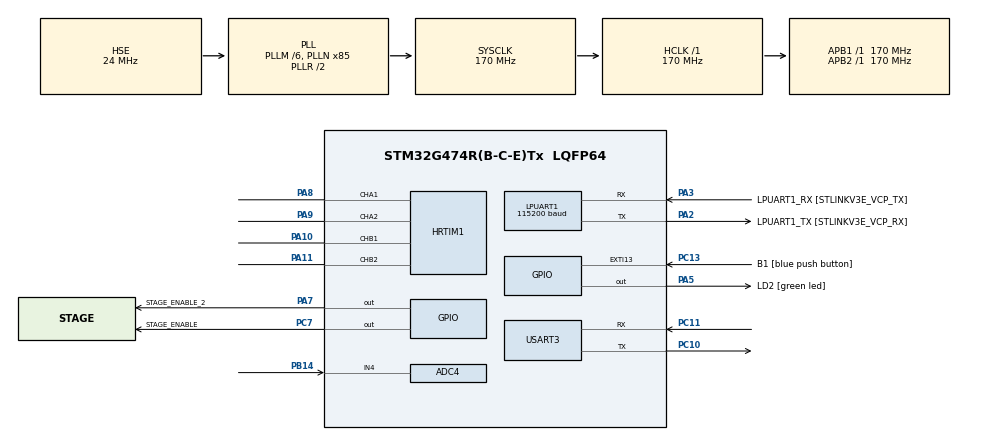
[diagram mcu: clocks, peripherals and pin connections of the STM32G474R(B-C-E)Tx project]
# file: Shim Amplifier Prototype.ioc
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ADC4.Channel-1\#ChannelRegularConversion=ADC_CHANNEL_4
ADC4.EOCSelection=ADC_EOC_SEQ_CONV
ADC4.ExternalTrigConv=ADC_EXTERNALTRIG_HRTIM_TRG1
ADC4.NbrOfConversion=1
ADC4.NbrOfConversionFlag=1
ADC4.OffsetNumber-1\#ChannelRegularConversion=ADC_OFFSET_NONE
ADC4.Overrun=ADC_OVR_DATA_OVERWRITTEN
ADC4.OversamplingMode=ENABLE
ADC4.OversamplingStopReset=ADC_REGOVERSAMPLING_RESUMED_MODE
ADC4.Rank-1\#ChannelRegularConversion=1
ADC4.RightBitShift=ADC_RIGHTBITSHIFT_1
ADC4.SamplingTime-1\#ChannelRegularConversion=ADC_SAMPLETIME_2CYCLES_5
ADC4.TriggeredMode=ADC_TRIGGEREDMODE_MULTI_TRIGGER
Dma.LPUART1_TX.0.Direction=DMA_MEMORY_TO_PERIPH
Dma.LPUART1_TX.0.EventEnable=DISABLE
Dma.LPUART1_TX.0.Instance=DMA1_Channel1
Dma.LPUART1_TX.0.MemDataAlignment=DMA_MDATAALIGN_BYTE
Dma.LPUART1_TX.0.MemInc=DMA_MINC_ENABLE
Dma.LPUART1_TX.0.Mode=DMA_NORMAL
Dma.LPUART1_TX.0.PeriphDataAlignment=DMA_PDATAALIGN_BYTE
Dma.LPUART1_TX.0.PeriphInc=DMA_PINC_DISABLE
Dma.LPUART1_TX.0.Polarity=HAL_DMAMUX_REQ_GEN_RISING
Dma.LPUART1_TX.0.Priority=DMA_PRIORITY_LOW
Dma.LPUART1_TX.0.RequestNumber=1
Dma.LPUART1_TX.0.SignalID=NONE
Dma.LPUART1_TX.0.SyncEnable=DISABLE
Dma.LPUART1_TX.0.SyncPolarity=HAL_DMAMUX_SYNC_NO_EVENT
Dma.LPUART1_TX.0.SyncRequestNumber=1
Dma.LPUART1_TX.0.SyncSignalID=NONE
Dma.Request0=LPUART1_TX
Dma.Request1=USART3_TX
Dma.USART3_TX.1.Direction=DMA_MEMORY_TO_PERIPH
Dma.USART3_TX.1.EventEnable=DISABLE
Dma.USART3_TX.1.Instance=DMA1_Channel2
Dma.USART3_TX.1.MemDataAlignment=DMA_MDATAALIGN_BYTE
Dma.USART3_TX.1.MemInc=DMA_MINC_ENABLE
Dma.USART3_TX.1.Mode=DMA_NORMAL
Dma.USART3_TX.1.PeriphDataAlignment=DMA_PDATAALIGN_BYTE
Dma.USART3_TX.1.PeriphInc=DMA_PINC_DISABLE
Dma.USART3_TX.1.Polarity=HAL_DMAMUX_REQ_GEN_RISING
Dma.USART3_TX.1.Priority=DMA_PRIORITY_LOW
Dma.USART3_TX.1.RequestNumber=1
Dma.USART3_TX.1.SignalID=NONE
Dma.USART3_TX.1.SyncEnable=DISABLE
Dma.USART3_TX.1.SyncPolarity=HAL_DMAMUX_SYNC_NO_EVENT
Dma.USART3_TX.1.SyncRequestNumber=1
Dma.USART3_TX.1.SyncSignalID=NONE
HRTIM1.ADCTrigger1_Source1=HRTIM_ADCTRIGGEREVENT13_MASTER_PERIOD
HRTIM1.ADCTrigger1_Source2=HRTIM_ADCTRIGGEREVENT13_MASTER_CMP2
HRTIM1.ADCTrigger2_Source1=HRTIM_ADCTRIGGEREVENT24_MASTER_CMP1
HRTIM1.ADCTrigger2_Source2=HRTIM_ADCTRIGGEREVENT24_MASTER_CMP3
HRTIM1.ADCTrigger_Id1=HRTIM_ADCTRIGGER_1
HRTIM1.ADCTrigger_Id2=HRTIM_ADCTRIGGER_2
HRTIM1.ADCTrigger_Id9=__NULL
HRTIM1.CompareUnit1-MasterTimer=HRTIM_COMPAREUNIT_1
HRTIM1.CompareUnit1-Output_TA1TA2=HRTIM_COMPAREUNIT_1
HRTIM1.CompareUnit1-Output_TB1TB2=HRTIM_COMPAREUNIT_1
HRTIM1.CompareUnit2-MasterTimer=HRTIM_COMPAREUNIT_2
HRTIM1.CompareUnit3-MasterTimer=HRTIM_COMPAREUNIT_3
HRTIM1.CompareUnit3-Output_TA1TA2=HRTIM_COMPAREUNIT_3
HRTIM1.CompareUnit3-Output_TB1TB2=HRTIM_COMPAREUNIT_3
HRTIM1.CompareValue1-Output_TA1TA2=0
HRTIM1.CompareValue1-Output_TB1TB2=2500
HRTIM1.CompareValue3-Output_TA1TA2=0
HRTIM1.CompareValue3-Output_TB1TB2=3500
HRTIM1.InterleavedMode-MasterTimer=HRTIM_INTERLEAVED_MODE_QUAD
HRTIM1.ModeTimeBase-MasterTimer=HRTIM_MODE_CONTINUOUS
HRTIM1.ModeTimeBase-Output_TA1TA2=HRTIM_MODE_SINGLESHOT_RETRIGGERABLE
HRTIM1.ModeTimeBase-Output_TB1TB2=HRTIM_MODE_SINGLESHOT_RETRIGGERABLE
HRTIM1.NumberADCTriggerSource1=2
HRTIM1.NumberADCTriggerSource2=2
HRTIM1.NumberInterruptRequests_Master-MasterTimer=0
HRTIM1.NumberResetSource1-Output_TA1TA2=1
HRTIM1.NumberResetSource1-Output_TB1TB2=1
HRTIM1.NumberResetSource2_TA=1
HRTIM1.NumberResetSource2_TB=1
HRTIM1.NumberResetTrigger-Output_TA1TA2=1
HRTIM1.NumberResetTrigger-Output_TB1TB2=1
HRTIM1.NumberSetSource1-Output_TA1TA2=1
HRTIM1.NumberSetSource1-Output_TB1TB2=1
HRTIM1.NumberSetSource2_TA=1
HRTIM1.NumberSetSource2_TB=1
HRTIM1.Periode_MASTER=4352
HRTIM1.PreloadEnable-Output_TA1TA2=HRTIM_PRELOAD_ENABLED
HRTIM1.PreloadEnable-Output_TB1TB2=HRTIM_PRELOAD_ENABLED
HRTIM1.ResetOutput1_Source1-Output_TA1TA2=HRTIM_OUTPUTRESET_TIMCMP1
HRTIM1.ResetOutput1_Source1-Output_TB1TB2=HRTIM_OUTPUTRESET_TIMCMP1
HRTIM1.ResetOutput2_Source1-Output_TA1TA2=HRTIM_OUTPUTRESET_TIMCMP3
HRTIM1.ResetOutput2_Source1-Output_TB1TB2=HRTIM_OUTPUTRESET_TIMCMP3
HRTIM1.ResetTrigger1-Output_TA1TA2=HRTIM_TIMRESETTRIGGER_MASTER_PER
HRTIM1.ResetTrigger1-Output_TB1TB2=HRTIM_TIMRESETTRIGGER_MASTER_PER
HRTIM1.ResetUpdate-Output_TB1TB2=HRTIM_TIMUPDATEONRESET_ENABLED
HRTIM1.SetOutput1_Source1-Output_TA1TA2=HRTIM_OUTPUTSET_MASTERPER
HRTIM1.SetOutput1_Source1-Output_TB1TB2=HRTIM_OUTPUTSET_MASTERPER
HRTIM1.SetOutput2_Source1-Output_TA1TA2=HRTIM_OUTPUTSET_MASTERPER
HRTIM1.SetOutput2_Source1-Output_TB1TB2=HRTIM_OUTPUTSET_MASTERPER
HRTIM1.SyncOptions=HRTIM_SYNCOPTION_NONE
HRTIM1.postscaler1=0x2
HRTIM1.postscaler2=0x2
LPUART1.BaudRate=115200
LPUART1.FIFOMode=UART_FIFOMODE_ENABLE
LPUART1.RXFIFOThreshold=UART_RXFIFO_THRESHOLD_8_8
LPUART1.TXFIFOThreshold=UART_TXFIFO_THRESHOLD_8_8
LPUART1.WordLength=UART_WORDLENGTH_8B
Mcu.Family=STM32G4
Mcu.Name=STM32G474R(B-C-E)Tx
Mcu.Package=LQFP64
NVIC.ADC4_IRQn=true\:0\:0\:false\:false\:false\:true\:true\:true
NVIC.DMA1_Channel1_IRQn=true\:2\:0\:true\:false\:true\:false\:true\:true
NVIC.DMA1_Channel2_IRQn=true\:2\:0\:true\:false\:true\:false\:true\:true
NVIC.LPUART1_IRQn=true\:1\:0\:true\:false\:true\:true\:true\:true
NVIC.PriorityGroup=NVIC_PRIORITYGROUP_4
NVIC.USART3_IRQn=true\:1\:0\:true\:false\:true\:true\:true\:true
PA10.Mode=Output_TB1TB2
PA10.Signal=HRTIM1_CHB1
PA11.Mode=Output_TB1TB2
PA11.Signal=HRTIM1_CHB2
PA13.GPIO_Label=T_SWDIO
PA13.Mode=Serial_Wire
PA13.Signal=SYS_JTMS-SWDIO
PA14.GPIO_Label=T_SWCLK
PA14.Mode=Serial_Wire
PA14.Signal=SYS_JTCK-SWCLK
PA2.GPIO_Label=LPUART1_TX [STLINKV3E_VCP_RX]
PA2.Mode=Asynchronous
PA2.Signal=LPUART1_TX
PA3.GPIO_Label=LPUART1_RX [STLINKV3E_VCP_TX]
PA3.Mode=Asynchronous
PA3.Signal=LPUART1_RX
PA5.GPIO_Label=LD2 [green led]
PA5.Signal=GPIO_Output
PA7.GPIO_Label=STAGE_ENABLE_2
PA7.Signal=GPIO_Output
PA8.Mode=Output_TA1TA2
PA8.Signal=HRTIM1_CHA1
PA9.Mode=Output_TA1TA2
PA9.Signal=HRTIM1_CHA2
PB14.Mode=IN4-Single-Ended
PB14.Signal=ADC4_IN4
PB3.GPIO_Label=T_SWO
PB3.Signal=SYS_JTDO-SWO
PC10.Mode=Asynchronous
PC10.Signal=USART3_TX
PC11.Mode=Asynchronous
PC11.Signal=USART3_RX
PC13.GPIO_Label=B1 [blue push button]
PC13.Signal=GPXTI13
PC14-OSC32_IN.Mode=LSE-External-Oscillator
PC14-OSC32_IN.Signal=RCC_OSC32_IN
PC15-OSC32_OUT.Mode=LSE-External-Oscillator
PC15-OSC32_OUT.Signal=RCC_OSC32_OUT
PC7.GPIO_Label=STAGE_ENABLE
PC7.GPIO_Speed=GPIO_SPEED_FREQ_LOW
PC7.Signal=GPIO_Output
PF0-OSC_IN.Mode=HSE-External-Oscillator
PF0-OSC_IN.Signal=RCC_OSC_IN
PF1-OSC_OUT.Mode=HSE-External-Oscillator
PF1-OSC_OUT.Signal=RCC_OSC_OUT
ProjectManager.HeapSize=0x200
ProjectManager.StackSize=0x400
ProjectManager.TargetToolchain=STM32CubeIDE
RCC.ADC12Freq_Value=170000000
RCC.ADC345Freq_Value=170000000
RCC.AHBFreq_Value=170000000
RCC.APB1Freq_Value=170000000
RCC.APB1TimFreq_Value=170000000
RCC.APB2Freq_Value=170000000
RCC.APB2TimFreq_Value=170000000
RCC.CortexFreq_Value=170000000
RCC.EXTERNAL_CLOCK_VALUE=12288000
RCC.HCLKFreq_Value=170000000
RCC.HSE_VALUE=24000000
RCC.HSI48_VALUE=48000000
RCC.HSI_VALUE=16000000
RCC.PLLM=RCC_PLLM_DIV6
RCC.PLLN=85
RCC.PLLSourceVirtual=RCC_PLLSOURCE_HSE
RCC.RTCClockSelection=RCC_RTCCLKSOURCE_LSE
RCC.SYSCLKFreq_VALUE=170000000
RCC.SYSCLKSource=RCC_SYSCLKSOURCE_PLLCLK
RCC.USBFreq_Value=170000000
RCC.VCOOutputFreq_Value=340000000
STMicroelectronics.X-CUBE-ALGOBUILD.1.3.0.LibraryCcDSPOoLibraryJjDSPOoLibrary=true
USART3.FIFOMode=FIFOMODE_ENABLE
USART3.RXFIFOThreshold=RXFIFO_THRESHOLD_FULL
USART3.TXFIFOThreshold=TXFIFO_THRESHOLD_EMPTY
USART3.VirtualMode-Asynchronous=VM_ASYNC
VP_HRTIM1_VS_hrtimMasterTimerNoOutput.Mode=MasterTimer
VP_STMicroelectronics.X-CUBE-ALGOBUILD_VS_DSPOoLibraryJjLibrary_1.3.0_1.3.0.Mode=DSPOoLibraryJjLibrary
VP_SYS_VS_DBSignals.Mode=DisableDeadBatterySignals
board=NUCLEO-G474RE

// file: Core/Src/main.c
/* USER CODE BEGIN Header */
/**
  ******************************************************************************
  * @file           : main.c
  * @brief          : Main program body
  ******************************************************************************
  * @attention
  *
  * Copyright (c) 2023 STMicroelectronics.
  * All rights reserved.
  *
  * This software is licensed under terms that can be found in the LICENSE file
  * in the root directory of this software component.
  * If no LICENSE file comes with this software, it is provided AS-IS.
  *
  ******************************************************************************
  */
/* USER CODE END Header */
#include "main.h"
#include "adc.h"
#include "dma.h"
#include "hrtim.h"
#include "usart.h"
#include "gpio.h"

/* USER CODE BEGIN Includes */
#include "app_main.h"
#include <stdbool.h>
/* USER CODE END Includes */

void SystemClock_Config(void);

int main(void)
{

  /* MCU Configuration--------------------------------------------------------*/

  /* Reset of all peripherals, Initializes the Flash interface and the Systick. */
  HAL_Init();

  /* Configure the system clock */
  SystemClock_Config();

  /* Initialize all configured peripherals */
  MX_GPIO_Init();
  MX_DMA_Init();
  MX_LPUART1_UART_Init();
  MX_HRTIM1_Init();
  MX_ADC4_Init();
  MX_USART3_UART_Init();
  /* USER CODE BEGIN 2 */
  //call the user app initialization routines
  app_init();
  /* USER CODE END 2 */

  /* Infinite loop */
  /* USER CODE BEGIN WHILE */
  while (1)
  {
	  //call the user app loop function
	  app_loop();
    /* USER CODE END WHILE */

  }
}

void SystemClock_Config(void)
{
  RCC_OscInitTypeDef RCC_OscInitStruct = {0};
  RCC_ClkInitTypeDef RCC_ClkInitStruct = {0};

  /** Configure the main internal regulator output voltage
  */
  HAL_PWREx_ControlVoltageScaling(PWR_REGULATOR_VOLTAGE_SCALE1_BOOST);

  /** Initializes the RCC Oscillators according to the specified parameters
  * in the RCC_OscInitTypeDef structure.
  */
  RCC_OscInitStruct.OscillatorType = RCC_OSCILLATORTYPE_HSE;
  RCC_OscInitStruct.HSEState = RCC_HSE_ON;
  RCC_OscInitStruct.PLL.PLLState = RCC_PLL_ON;
  RCC_OscInitStruct.PLL.PLLSource = RCC_PLLSOURCE_HSE;
  RCC_OscInitStruct.PLL.PLLM = RCC_PLLM_DIV6;
  RCC_OscInitStruct.PLL.PLLN = 85;
  RCC_OscInitStruct.PLL.PLLP = RCC_PLLP_DIV2;
  RCC_OscInitStruct.PLL.PLLQ = RCC_PLLQ_DIV2;
  RCC_OscInitStruct.PLL.PLLR = RCC_PLLR_DIV2;
  if (HAL_RCC_OscConfig(&RCC_OscInitStruct) != HAL_OK)
  {
    Error_Handler();
  }

  /** Initializes the CPU, AHB and APB buses clocks
  */
  RCC_ClkInitStruct.ClockType = RCC_CLOCKTYPE_HCLK|RCC_CLOCKTYPE_SYSCLK
                              |RCC_CLOCKTYPE_PCLK1|RCC_CLOCKTYPE_PCLK2;
  RCC_ClkInitStruct.SYSCLKSource = RCC_SYSCLKSOURCE_PLLCLK;
  RCC_ClkInitStruct.AHBCLKDivider = RCC_SYSCLK_DIV1;
  RCC_ClkInitStruct.APB1CLKDivider = RCC_HCLK_DIV1;
  RCC_ClkInitStruct.APB2CLKDivider = RCC_HCLK_DIV1;

  if (HAL_RCC_ClockConfig(&RCC_ClkInitStruct, FLASH_LATENCY_4) != HAL_OK)
  {
    Error_Handler();
  }
}

void Error_Handler(void)
{
  __disable_irq();
  while (1)
  {
  }
}
